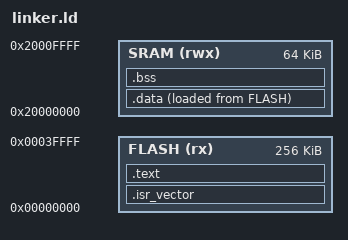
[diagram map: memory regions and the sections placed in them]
ENTRY(reset_handler)

MEMORY
{
    FLASH (rx)  : ORIGIN = 0x00000000, LENGTH = 256K
    SRAM  (rwx) : ORIGIN = 0x20000000, LENGTH = 64K
}

_estack = ORIGIN(SRAM) + LENGTH(SRAM);

SECTIONS
{
    .isr_vector : {
        KEEP(*(.isr_vector))
    } > FLASH

    .text : {
        *(.text*)
        *(.rodata*)
    } > FLASH

    .data : {
        _sdata = .;
        *(.data*)
        _edata = .;
    } > SRAM AT > FLASH
    _sidata = LOADADDR(.data);

    .bss : {
        _sbss = .;
        *(.bss*)
        *(COMMON)
        _ebss = .;
    } > SRAM
}
